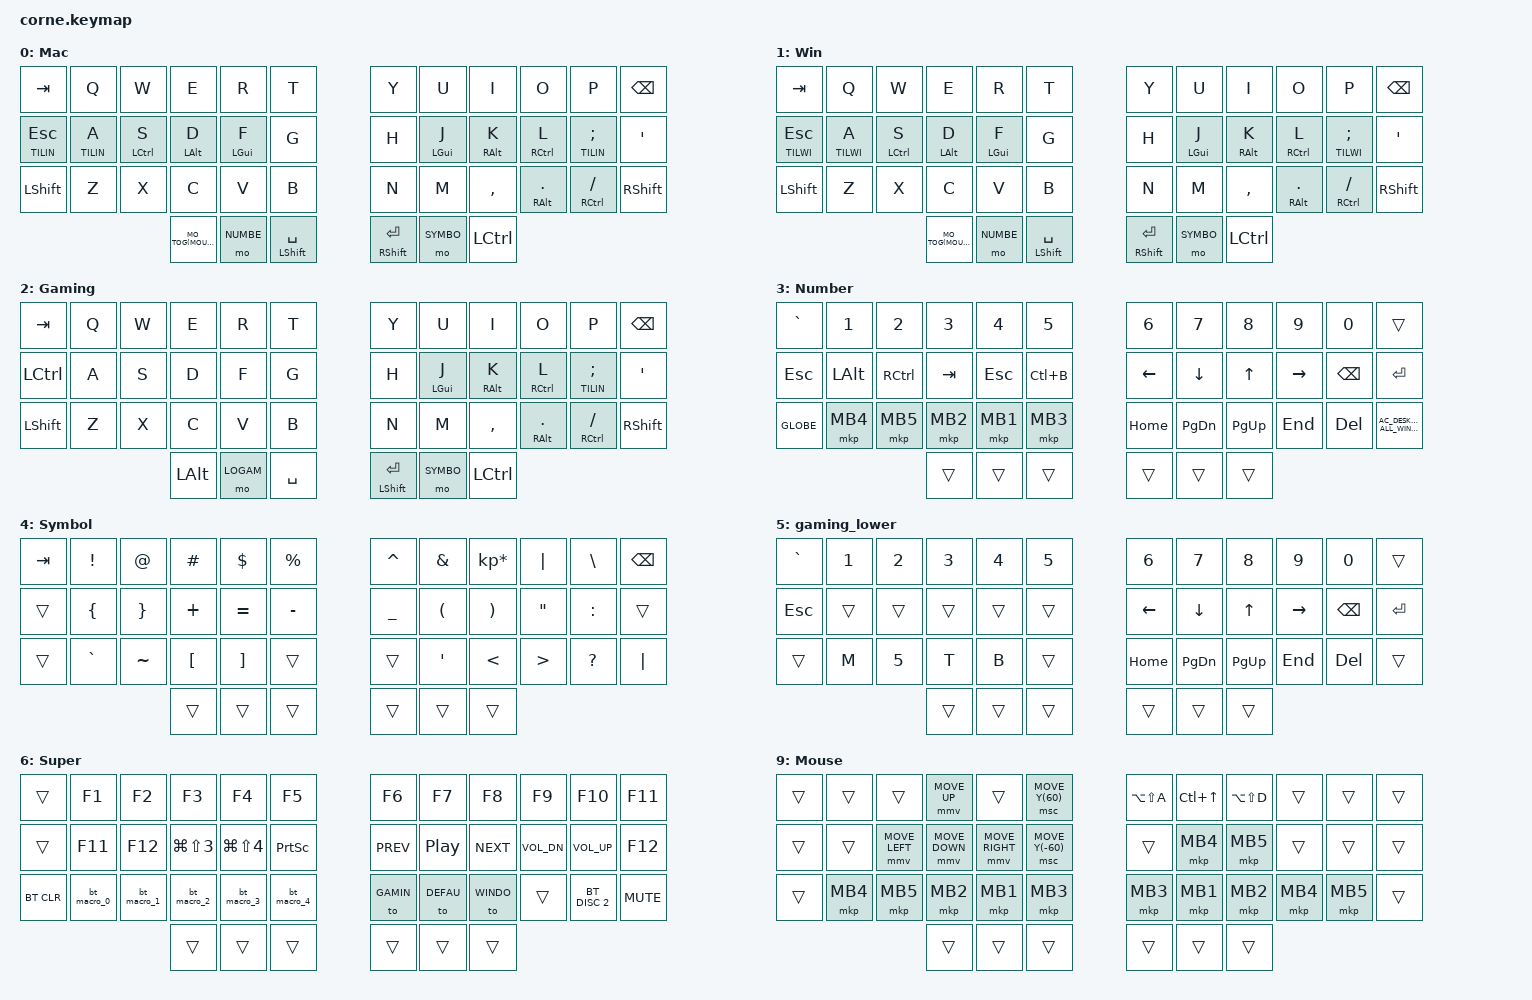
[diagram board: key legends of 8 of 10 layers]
/*

 * Copyright (c) 2020 The ZMK Contributors
 *
 * SPDX-License-Identifier: MIT
 */

#include <dt-bindings/zmk/mouse.h>
#include <behaviors.dtsi>
#include <dt-bindings/zmk/bt.h>
#include <dt-bindings/zmk/keys.h>

#define DEFAU 0
#define WINDO 1
#define GAMIN 2
#define NUMBE 3
#define SYMBO 4
#define LOGAM 5
#define SUPER 6
#define TILIN 7
#define TILWI 8
#define MOUSE 9

&nice_view_spi { cs-gpios = <&pro_micro 0 GPIO_ACTIVE_HIGH>; };

#define MO_TOG(layer) &mo_tog layer layer   // Macro to apply momentary-layer-on-hold/toggle-layer-on-tap to a specific layer

&kscan0 {
    debounce-press-ms = <1>;
    debounce-release-ms = <5>;
};

/ {
    conditional_layers {
        compatible = "zmk,conditional-layers";

        tri_layer {
            if-layers = <NUMBE SYMBO>;
            then-layer = <SUPER>;
        };

        tri_layer_gaming {
            if-layers = <SYMBO LOGAM>;
            then-layer = <SUPER>;
        };
    };

    behaviors {
        hm: homerow_mods {
            compatible = "zmk,behavior-hold-tap";
            label = "HOMEROW_MODS";
            #binding-cells = <2>;
            tapping-term-ms = <200>;
            quick-tap-ms = <0>;
            flavor = "tap-preferred";
            bindings = <&kp>, <&kp>;
        };

        hk: homerow_hold {
            compatible = "zmk,behavior-hold-tap";
            label = "HOLD_MOD";
            #binding-cells = <2>;
            tapping-term-ms = <150>;
            quick-tap-ms = <0>;
            flavor = "hold-preferred";
            bindings = <&kp>, <&kp>;
        };

        hs: hold_custom {
            compatible = "zmk,behavior-hold-tap";
            label = "HOLD_CUSTOM";
            #binding-cells = <2>;
            tapping-term-ms = <500>;
            quick-tap-ms = <0>;
            flavor = "tap-preferred";
            bindings = <&kp>, <&kp>;
        };
        mo_tog: behavior_mo_tog {
            compatible = "zmk,behavior-hold-tap";
            #binding-cells = <2>;
            flavor = "hold-preferred";
            tapping-term-ms = <200>;
            bindings = <&mo>, <&tog>;
        };
        swap: swapper {
            compatible = "zmk,behavior-tri-state";
            label = "SWAPPER";
            #binding-cells = <0>;
            bindings = <&kt LALT>, <&kp TAB>, <&kt LALT>;
            ignored-key-positions = <26>;
        };
        w1: w1 {
            compatible = "zmk,behavior-tri-state";
            label = "WIN OPEN 1";
            #binding-cells = <0>;
            bindings = <&kt LGUI>, <&kp N1>, <&kt LGUI>;
        };

        w2: w2 {
            compatible = "zmk,behavior-tri-state";
            label = "WIN OPEN 2";
            #binding-cells = <0>;
            bindings = <&kt LGUI>, <&kp N2>, <&kt LGUI>;
        };

        w3: w3 {
            compatible = "zmk,behavior-tri-state";
            label = "WIN OPEN 3";
            #binding-cells = <0>;
            bindings = <&kt LGUI>, <&kp N3>, <&kt LGUI>;
        };

        w4: w4 {
            compatible = "zmk,behavior-tri-state";
            label = "WIN OPEN 4";
            #binding-cells = <0>;
            bindings = <&kt LGUI>, <&kp N4>, <&kt LGUI>;
        };

        w5: w5 {
            compatible = "zmk,behavior-tri-state";
            label = "WIN OPEN 5";
            #binding-cells = <0>;
            bindings = <&kt LGUI>, <&kp N5>, <&kt LGUI>;
        };

        w6: w6 {
            compatible = "zmk,behavior-tri-state";
            label = "WIN OPEN 6";
            #binding-cells = <0>;
            bindings = <&kt LGUI>, <&kp N6>, <&kt LGUI>;
        };

        w7: w7 {
            compatible = "zmk,behavior-tri-state";
            label = "WIN OPEN 7";
            #binding-cells = <0>;
            bindings = <&kt LGUI>, <&kp N7>, <&kt LGUI>;
        };

        w8: w8 {
            compatible = "zmk,behavior-tri-state";
            label = "WIN OPEN 8";
            #binding-cells = <0>;
            bindings = <&kt LGUI>, <&kp N8>, <&kt LGUI>;
        };

        w9: w9 {
            compatible = "zmk,behavior-tri-state";
            label = "WIN OPEN 9";
            #binding-cells = <0>;
            bindings = <&kt LGUI>, <&kp N9>, <&kt LGUI>;
        };
    };

    macros {
        bt_macro_0: bt_macro_0 {
            label = "bt_macro_0";
            compatible = "zmk,behavior-macro";
            #binding-cells = <0>;
            wait-ms = <0>;
            tap-ms = <0>;
            bindings = <&to DEFAU>,  <&bt BT_SEL 0>;
        };

        bt_macro_1: bt_macro_1 {
            label = "bt_macro_1";
            compatible = "zmk,behavior-macro";
            #binding-cells = <0>;
            wait-ms = <0>;
            tap-ms = <0>;
            bindings = <&to DEFAU>,  <&bt BT_SEL 1>;
        };

        bt_macro_2: bt_macro_2 {
            label = "bt_macro_2";
            compatible = "zmk,behavior-macro";
            #binding-cells = <0>;
            wait-ms = <0>;
            tap-ms = <0>;
            bindings = <&to DEFAU>,  <&bt BT_SEL 2>;
        };

        bt_macro_3: bt_macro_3 {
            label = "bt_macro_3";
            compatible = "zmk,behavior-macro";
            #binding-cells = <0>;
            wait-ms = <0>;
            tap-ms = <0>;
            bindings = <&to WINDO>,  <&bt BT_SEL 3>;
        };

        bt_macro_4: bt_macro_4 {
            label = "bt_macro_4";
            compatible = "zmk,behavior-macro";
            #binding-cells = <0>;
            wait-ms = <0>;
            tap-ms = <0>;
            bindings = <&to WINDO>,  <&bt BT_SEL 4>;
        };
    };

    keymap {
        compatible = "zmk,keymap";

        default_layer {
            label = "Mac";
            bindings = <
&kp TAB    &kp Q    &kp W        &kp E       &kp R       &kp T              &kp Y          &kp U       &kp I       &kp O         &kp P           &kp BSPC
&lt TILIN ESC  &lt TILIN A  &hm LCTRL S  &hm LALT D  &hm LGUI F  &kp G              &kp H          &hm LGUI J  &hm RALT K  &hm RCTRL L   &lt TILIN SEMI      &kp SQT
&kp LSHFT  &kp Z    &kp X        &kp C       &kp V       &kp B              &kp N          &kp M       &kp COMMA   &hm RALT DOT  &hm RCTRL FSLH  &kp RSHFT
                                 MO_TOG(MOUSE)  &mo NUMBE       &hm LSHFT SPACE    &hk RSHFT RET  &mo SYMBO       &kp LCTRL
            >;
        };

        windows {
            label = "Win";
            bindings = <
&kp TAB    &kp Q    &kp W        &kp E       &kp R       &kp T              &kp Y          &kp U       &kp I       &kp O         &kp P           &kp BSPC
&lt TILWI ESC  &lt TILWI A  &hm LCTRL S  &hm LALT D  &hm LGUI F  &kp G              &kp H          &hm LGUI J  &hm RALT K  &hm RCTRL L   &lt TILWI SEMI      &kp SQT
&kp LSHFT  &kp Z    &kp X        &kp C       &kp V       &kp B              &kp N          &kp M       &kp COMMA   &hm RALT DOT  &hm RCTRL FSLH  &kp RSHFT
                                 MO_TOG(MOUSE)   &mo NUMBE       &hm LSHFT SPACE    &hk RSHFT RET  &mo SYMBO       &kp LCTRL
            >;
        };

        gaming_layer {
            label = "Gaming";
            bindings = <
&kp TAB    &kp Q  &kp W  &kp E         &kp R  &kp T        &kp Y          &kp U       &kp I       &kp O         &kp P           &kp BSPC
&kp LCTRL  &kp A  &kp S  &kp D         &kp F  &kp G        &kp H          &hm LGUI J  &hm RALT K  &hm RCTRL L   &lt TILIN SEMI      &kp SQT
&kp LSHFT  &kp Z  &kp X  &kp C         &kp V  &kp B        &kp N          &kp M       &kp COMMA   &hm RALT DOT  &hm RCTRL FSLH  &kp RSHFT
                         &kp LEFT_ALT  &mo LOGAM  &kp SPACE    &hk LSHFT RET  &mo SYMBO       &kp LCTRL
            >;
        };

        lower_layer {
            label = "Number";
            bindings = <
&kp GRAVE  &kp N1     &kp N2     &kp N3    &kp N4    &kp N5       &kp N6    &kp N7     &kp N8     &kp N9     &kp N0    &trans
&kp ESC    &kp LALT   &kp RCTRL  &kp TAB   &kp ESC   &kp LC(B)    &kp LEFT  &kp DOWN   &kp UP     &kp RIGHT  &kp BSPC  &kp RET
&kp GLOBE  &mkp MB4   &mkp MB5   &mkp MB2  &mkp MB1  &mkp MB3     &kp HOME  &kp PG_DN  &kp PG_UP  &kp END    &kp DEL   &kp C_AC_DESKTOP_SHOW_ALL_WINDOWS
                                 &trans    &trans    &trans       &trans    &trans     &trans
            >;
        };

        raise_layer {
            label = "Symbol";
            bindings = <
&kp TAB  &kp EXCL   &kp AT     &kp HASH  &kp DLLR   &kp PRCNT    &kp CARET  &kp AMPS  &kp KP_MULTIPLY  &kp PIPE  &kp BSLH   &kp BSPC
&trans   &kp LBRC   &kp RBRC   &kp PLUS  &kp EQUAL  &kp MINUS    &kp UNDER  &kp LPAR  &kp RPAR         &kp DQT   &kp COLON  &trans
&trans   &kp GRAVE  &kp TILDE  &kp LBKT  &kp RBKT   &trans       &trans     &kp SQT   &kp LT           &kp GT    &kp QMARK  &kp PIPE
                               &trans    &trans     &trans       &trans     &trans    &trans
            >;
        };

        gaming_lower {
            bindings = <
&kp GRAVE  &kp N1     &kp N2     &kp N3    &kp N4    &kp N5      &kp N6    &kp N7     &kp N8     &kp N9     &kp N0    &trans
&kp ESC    &trans     &trans     &trans    &trans    &trans      &kp LEFT  &kp DOWN   &kp UP     &kp RIGHT  &kp BSPC  &kp RET
&trans     &kp M      &kp N5    &kp T     &kp B      &trans      &kp HOME  &kp PG_DN  &kp PG_UP  &kp END    &kp DEL   &trans
                                 &trans    &trans    &trans      &trans    &trans     &trans
            >;
        };

        super_layer {
            label = "Super";
            bindings = <
&trans      &kp F1        &kp F2        &kp F3          &kp F4          &kp F5          &kp F6      &kp F7    &kp F8      &kp F9        &kp F10       &kp F11
&trans      &kp F11       &kp F12       &kp LG(LS(N3))  &kp LG(LS(N4))  &kp PSCRN       &kp C_PREV  &kp C_PP  &kp C_NEXT  &kp C_VOL_DN  &kp C_VOL_UP  &kp F12
&bt BT_CLR  &bt_macro_0   &bt_macro_1   &bt_macro_2     &bt_macro_3     &bt_macro_4     &to GAMIN      &to DEFAU    &to WINDO      &trans        &bt BT_DISC 2 &kp C_MUTE
                                        &trans          &trans          &trans          &trans      &trans    &trans
            >;
        };

        tiling_layer {
            label = "Tiling";
            bindings = <
&trans  &hs LC(LA(LS(N1))) LA(LS(N1))  &hs LC(LA(LS(N2))) LA(LS(N2))  &hs LC(LA(LS(N3))) LA(LS(N3))  &hs LC(LA(LS(N4))) LA(LS(N4))  &hs LC(LA(LS(N5))) LA(LS(N5))    &hs LC(LA(LS(N6))) LA(LS(N6))  &hs LC(LA(LS(N7))) LA(LS(N7))  &hs LC(LA(LS(N8))) LA(LS(N8))  &hs LC(LA(LS(N9))) LA(LS(N9))  &trans  &trans
&trans  &trans                         &kp LA(LS(W))                  &hs LC(LA(LS(E))) LA(LS(E))    &hs LC(LA(LS(R))) LA(LS(R))    &hs LC(LA(LS(T))) LA(LS(T))      &trans                         &trans                         &trans                         &trans                         &trans  &trans
&trans  &kp LA(LS(A))                  &kp LA(LS(S))                  &kp LA(LS(D))                  &trans                         &trans                           &trans                         &trans                         &trans                         &trans                         &trans  &trans
                                                                      &trans                         &trans                         &kp LG(SPACE)                    &trans                         &trans                         &trans
            >;
        };

        tiling_win_layer {
            label = "TWin";
            bindings = <
&trans  &w1           &w2             &w3                         &w4                         &w5                           &w6          &w7         &w8         &w9        &trans  &trans
&trans  &trans        &swap           &hs LC(LA(LS(E))) LA(LS(E)) &hs LC(LA(LS(R))) LA(LS(R)) &hs LC(LA(LS(T))) LA(LS(T))   &trans       &trans      &trans      &trans                         &trans  &trans
&trans  &kp LA(LS(D)) &kp LS(TAB)     &kp LA(LS(D))               &trans                      &trans                        &trans       &trans      &trans                      &trans                      &trans  &trans
                                                                  &trans                      &trans                         &kp LGUI                    &trans                         &trans                         &trans
            >;
        };

        mouse_layer {
            label = "Mouse";
            bindings = <
&trans          &trans          &trans          &mmv MOVE_UP    &trans          &msc MOVE_Y(60)              &kp LA(LS(A))   &kp LC(UP)      &kp LA(LS(D))     &trans          &trans          &trans
&trans          &trans          &mmv MOVE_LEFT  &mmv MOVE_DOWN  &mmv MOVE_RIGHT &msc MOVE_Y(-60)             &trans          &mkp MB4        &mkp MB5          &trans          &trans          &trans
&trans          &mkp MB4        &mkp MB5        &mkp MB2        &mkp MB1        &mkp MB3                      &mkp MB3        &mkp MB1        &mkp MB2          &mkp MB4        &mkp MB5        &trans
                                 &trans    &trans    &trans       &trans    &trans     &trans
            >;
        };
    };
};
